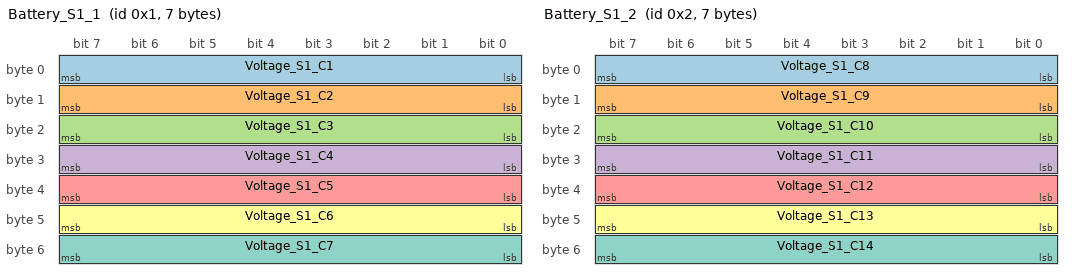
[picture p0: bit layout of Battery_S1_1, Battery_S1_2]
BO_ 1 Battery_S1_1: 7 Vector_XXX
        SG_ Voltage_S1_C1 : 0|8@1+ (0.01,2.2) [0|4.75] "V"
        SG_ Voltage_S1_C2 : 8|8@1+ (0.01,2.2) [0|4.75] "V"
        SG_ Voltage_S1_C3 : 16|8@1+ (0.01,2.2) [0|4.75] "V"
        SG_ Voltage_S1_C4 : 24|8@1+ (0.01,2.2) [0|4.75] "V"
        SG_ Voltage_S1_C5 : 32|8@1+ (0.01,2.2) [0|4.75] "V"
        SG_ Voltage_S1_C6 : 40|8@1+ (0.01,2.2) [0|4.75] "V"
        SG_ Voltage_S1_C7 : 48|8@1+ (0.01,2.2) [0|4.75] "V"

BO_ 2 Battery_S1_2: 7 Vector_XXX
        SG_ Voltage_S1_C8 : 0|8@1+ (0.01,2.2) [0|4.75] "V"
        SG_ Voltage_S1_C9 : 8|8@1+ (0.01,2.2) [0|4.75] "V"
        SG_ Voltage_S1_C10 : 16|8@1+ (0.01,2.2) [0|4.75] "V"
        SG_ Voltage_S1_C11 : 24|8@1+ (0.01,2.2) [0|4.75] "V"
        SG_ Voltage_S1_C12 : 32|8@1+ (0.01,2.2) [0|4.75] "V"
        SG_ Voltage_S1_C13 : 40|8@1+ (0.01,2.2) [0|4.75] "V"
        SG_ Voltage_S1_C14 : 48|8@1+ (0.01,2.2) [0|4.75] "V"

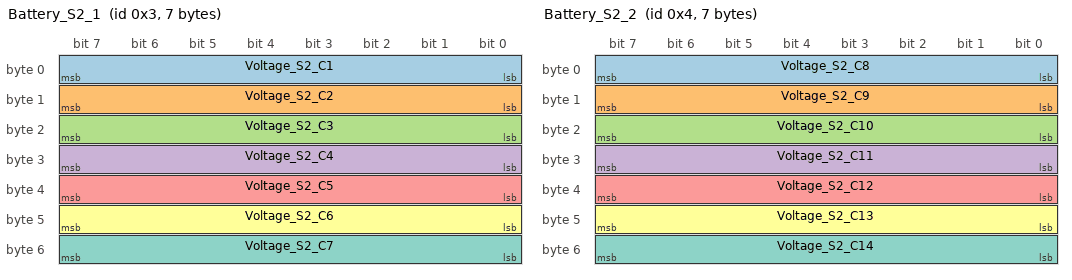
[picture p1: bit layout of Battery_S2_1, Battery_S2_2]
BO_ 3 Battery_S2_1: 7 Vector_XXX
        SG_ Voltage_S2_C1 : 0|8@1+ (0.01,2.2) [0|4.75] "V"
        SG_ Voltage_S2_C2 : 8|8@1+ (0.01,2.2) [0|4.75] "V"
        SG_ Voltage_S2_C3 : 16|8@1+ (0.01,2.2) [0|4.75] "V"
        SG_ Voltage_S2_C4 : 24|8@1+ (0.01,2.2) [0|4.75] "V"
        SG_ Voltage_S2_C5 : 32|8@1+ (0.01,2.2) [0|4.75] "V"
        SG_ Voltage_S2_C6 : 40|8@1+ (0.01,2.2) [0|4.75] "V"
        SG_ Voltage_S2_C7 : 48|8@1+ (0.01,2.2) [0|4.75] "V"

BO_ 4 Battery_S2_2: 7 Vector_XXX
        SG_ Voltage_S2_C8 : 0|8@1+ (0.01,2.2) [0|4.75] "V"
        SG_ Voltage_S2_C9 : 8|8@1+ (0.01,2.2) [0|4.75] "V"
        SG_ Voltage_S2_C10 : 16|8@1+ (0.01,2.2) [0|4.75] "V"
        SG_ Voltage_S2_C11 : 24|8@1+ (0.01,2.2) [0|4.75] "V"
        SG_ Voltage_S2_C12 : 32|8@1+ (0.01,2.2) [0|4.75] "V"
        SG_ Voltage_S2_C13 : 40|8@1+ (0.01,2.2) [0|4.75] "V"
        SG_ Voltage_S2_C14 : 48|8@1+ (0.01,2.2) [0|4.75] "V"

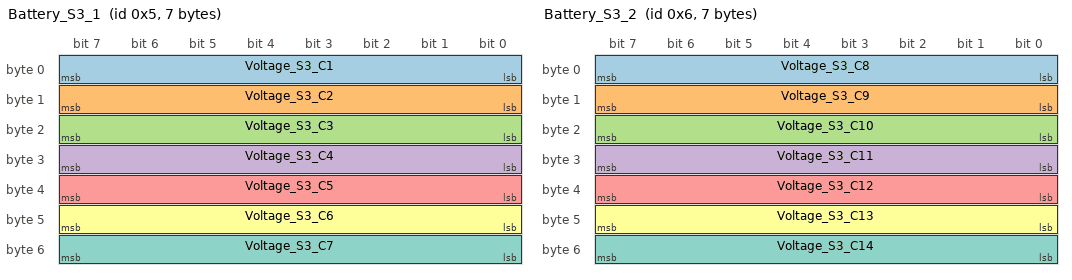
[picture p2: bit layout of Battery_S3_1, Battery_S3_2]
BO_ 5 Battery_S3_1:  7 Vector_XXX
        SG_ Voltage_S3_C1 : 0|8@1+ (0.01,2.2) [0|4.75] "V"
        SG_ Voltage_S3_C2 : 8|8@1+ (0.01,2.2) [0|4.75] "V"
        SG_ Voltage_S3_C3 : 16|8@1+ (0.01,2.2) [0|4.75] "V"
        SG_ Voltage_S3_C4 : 24|8@1+ (0.01,2.2) [0|4.75] "V"
        SG_ Voltage_S3_C5 : 32|8@1+ (0.01,2.2) [0|4.75] "V"
        SG_ Voltage_S3_C6 : 40|8@1+ (0.01,2.2) [0|4.75] "V"
        SG_ Voltage_S3_C7 : 48|8@1+ (0.01,2.2) [0|4.75] "V"

BO_ 6 Battery_S3_2: 7 Vector_XXX
        SG_ Voltage_S3_C8 : 0|8@1+ (0.01,2.2) [0|4.75] "V"
        SG_ Voltage_S3_C9 : 8|8@1+ (0.01,2.2) [0|4.75] "V"
        SG_ Voltage_S3_C10 : 16|8@1+ (0.01,2.2) [0|4.75] "V"
        SG_ Voltage_S3_C11 : 24|8@1+ (0.01,2.2) [0|4.75] "V"
        SG_ Voltage_S3_C12 : 32|8@1+ (0.01,2.2) [0|4.75] "V"
        SG_ Voltage_S3_C13 : 40|8@1+ (0.01,2.2) [0|4.75] "V"
        SG_ Voltage_S3_C14 : 48|8@1+ (0.01,2.2) [0|4.75] "V"

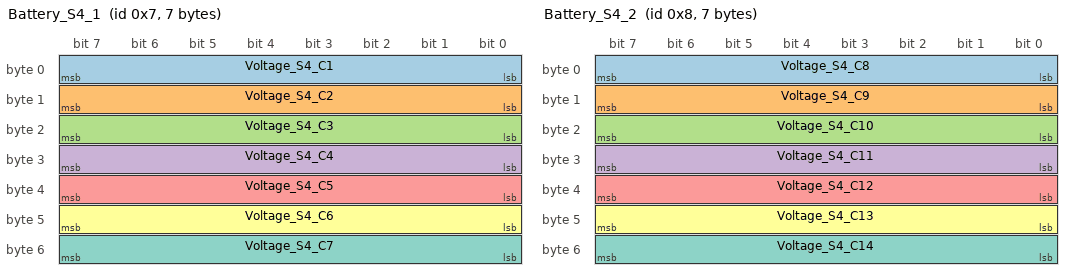
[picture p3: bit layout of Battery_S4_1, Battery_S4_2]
BO_ 7 Battery_S4_1: 7 Vector_XXX
        SG_ Voltage_S4_C1 : 0|8@1+ (0.01,2.2) [0|4.75] "V"
        SG_ Voltage_S4_C2 : 8|8@1+ (0.01,2.2) [0|4.75] "V"
        SG_ Voltage_S4_C3 : 16|8@1+ (0.01,2.2) [0|4.75] "V"
        SG_ Voltage_S4_C4 : 24|8@1+ (0.01,2.2) [0|4.75] "V"
        SG_ Voltage_S4_C5 : 32|8@1+ (0.01,2.2) [0|4.75] "V"
        SG_ Voltage_S4_C6 : 40|8@1+ (0.01,2.2) [0|4.75] "V"
        SG_ Voltage_S4_C7 : 48|8@1+ (0.01,2.2) [0|4.75] "V"

BO_ 8 Battery_S4_2: 7 Vector_XXX
        SG_ Voltage_S4_C8 : 0|8@1+ (0.01,2.2) [0|4.75] "V"
        SG_ Voltage_S4_C9 : 8|8@1+ (0.01,2.2) [0|4.75] "V"
        SG_ Voltage_S4_C10 : 16|8@1+ (0.01,2.2) [0|4.75] "V"
        SG_ Voltage_S4_C11 : 24|8@1+ (0.01,2.2) [0|4.75] "V"
        SG_ Voltage_S4_C12 : 32|8@1+ (0.01,2.2) [0|4.75] "V"
        SG_ Voltage_S4_C13 : 40|8@1+ (0.01,2.2) [0|4.75] "V"
        SG_ Voltage_S4_C14 : 48|8@1+ (0.01,2.2) [0|4.75] "V"

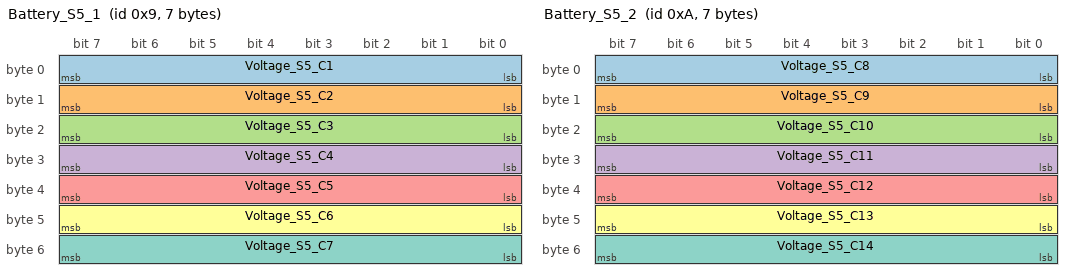
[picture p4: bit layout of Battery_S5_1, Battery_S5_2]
BO_ 9 Battery_S5_1: 7 Vector_XXX
        SG_ Voltage_S5_C1 : 0|8@1+ (0.01,2.2) [0|4.75] "V"
        SG_ Voltage_S5_C2 : 8|8@1+ (0.01,2.2) [0|4.75] "V"
        SG_ Voltage_S5_C3 : 16|8@1+ (0.01,2.2) [0|4.75] "V"
        SG_ Voltage_S5_C4 : 24|8@1+ (0.01,2.2) [0|4.75] "V"
        SG_ Voltage_S5_C5 : 32|8@1+ (0.01,2.2) [0|4.75] "V"
        SG_ Voltage_S5_C6 : 40|8@1+ (0.01,2.2) [0|4.75] "V"
        SG_ Voltage_S5_C7 : 48|8@1+ (0.01,2.2) [0|4.75] "V"

BO_ 10 Battery_S5_2: 7 Vector_XXX
        SG_ Voltage_S5_C8 : 0|8@1+ (0.01,2.2) [0|4.75] "V"
        SG_ Voltage_S5_C9 : 8|8@1+ (0.01,2.2) [0|4.75] "V"
        SG_ Voltage_S5_C10 : 16|8@1+ (0.01,2.2) [0|4.75] "V"
        SG_ Voltage_S5_C11 : 24|8@1+ (0.01,2.2) [0|4.75] "V"
        SG_ Voltage_S5_C12 : 32|8@1+ (0.01,2.2) [0|4.75] "V"
        SG_ Voltage_S5_C13 : 40|8@1+ (0.01,2.2) [0|4.75] "V"
        SG_ Voltage_S5_C14 : 48|8@1+ (0.01,2.2) [0|4.75] "V"

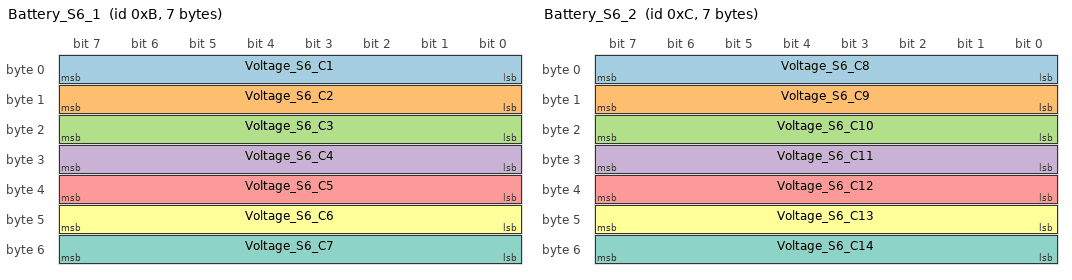
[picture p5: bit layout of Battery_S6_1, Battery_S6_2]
BO_ 11 Battery_S6_1: 7 Vector_XXX
        SG_ Voltage_S6_C1 : 0|8@1+ (0.01,2.2) [0|4.75] "V"
        SG_ Voltage_S6_C2 : 8|8@1+ (0.01,2.2) [0|4.75] "V"
        SG_ Voltage_S6_C3 : 16|8@1+ (0.01,2.2) [0|4.75] "V"
        SG_ Voltage_S6_C4 : 24|8@1+ (0.01,2.2) [0|4.75] "V"
        SG_ Voltage_S6_C5 : 32|8@1+ (0.01,2.2) [0|4.75] "V"
        SG_ Voltage_S6_C6 : 40|8@1+ (0.01,2.2) [0|4.75] "V"
        SG_ Voltage_S6_C7 : 48|8@1+ (0.01,2.2) [0|4.75] "V"

BO_ 12 Battery_S6_2: 7 Vector_XXX
        SG_ Voltage_S6_C8 : 0|8@1+ (0.01,2.2) [0|4.75] "V"
        SG_ Voltage_S6_C9 : 8|8@1+ (0.01,2.2) [0|4.75] "V"
        SG_ Voltage_S6_C10 : 16|8@1+ (0.01,2.2) [0|4.75] "V"
        SG_ Voltage_S6_C11 : 24|8@1+ (0.01,2.2) [0|4.75] "V"
        SG_ Voltage_S6_C12 : 32|8@1+ (0.01,2.2) [0|4.75] "V"
        SG_ Voltage_S6_C13 : 40|8@1+ (0.01,2.2) [0|4.75] "V"
        SG_ Voltage_S6_C14 : 48|8@1+ (0.01,2.2) [0|4.75] "V"

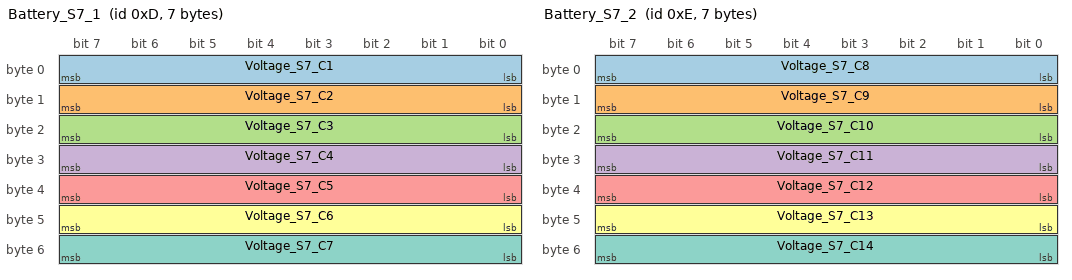
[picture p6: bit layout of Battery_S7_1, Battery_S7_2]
BO_ 13 Battery_S7_1: 7 Vector_XXX
        SG_ Voltage_S7_C1 : 0|8@1+ (0.01,2.2) [0|4.75] "V"
        SG_ Voltage_S7_C2 : 8|8@1+ (0.01,2.2) [0|4.75] "V"
        SG_ Voltage_S7_C3 : 16|8@1+ (0.01,2.2) [0|4.75] "V"
        SG_ Voltage_S7_C4 : 24|8@1+ (0.01,2.2) [0|4.75] "V"
        SG_ Voltage_S7_C5 : 32|8@1+ (0.01,2.2) [0|4.75] "V"
        SG_ Voltage_S7_C6 : 40|8@1+ (0.01,2.2) [0|4.75] "V"
        SG_ Voltage_S7_C7 : 48|8@1+ (0.01,2.2) [0|4.75] "V"

BO_ 14 Battery_S7_2: 7 Vector_XXX
        SG_ Voltage_S7_C8 : 0|8@1+ (0.01,2.2) [0|4.75] "V"
        SG_ Voltage_S7_C9 : 8|8@1+ (0.01,2.2) [0|4.75] "V"
        SG_ Voltage_S7_C10 : 16|8@1+ (0.01,2.2) [0|4.75] "V"
        SG_ Voltage_S7_C11 : 24|8@1+ (0.01,2.2) [0|4.75] "V"
        SG_ Voltage_S7_C12 : 32|8@1+ (0.01,2.2) [0|4.75] "V"
        SG_ Voltage_S7_C13 : 40|8@1+ (0.01,2.2) [0|4.75] "V"
        SG_ Voltage_S7_C14 : 48|8@1+ (0.01,2.2) [0|4.75] "V"

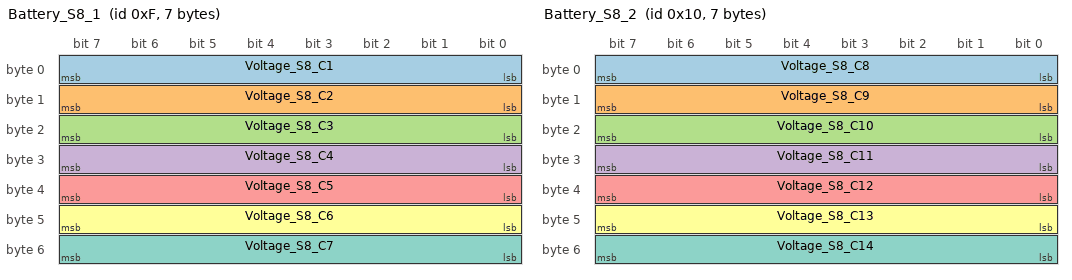
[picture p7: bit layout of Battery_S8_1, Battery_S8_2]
BO_ 15 Battery_S8_1: 7 Vector_XXX
        SG_ Voltage_S8_C1 : 0|8@1+ (0.01,2.2) [0|4.75] "V"
        SG_ Voltage_S8_C2 : 8|8@1+ (0.01,2.2) [0|4.75] "V"
        SG_ Voltage_S8_C3 : 16|8@1+ (0.01,2.2) [0|4.75] "V"
        SG_ Voltage_S8_C4 : 24|8@1+ (0.01,2.2) [0|4.75] "V"
        SG_ Voltage_S8_C5 : 32|8@1+ (0.01,2.2) [0|4.75] "V"
        SG_ Voltage_S8_C6 : 40|8@1+ (0.01,2.2) [0|4.75] "V"
        SG_ Voltage_S8_C7 : 48|8@1+ (0.01,2.2) [0|4.75] "V"

BO_ 16 Battery_S8_2: 7 Vector_XXX
        SG_ Voltage_S8_C8 : 0|8@1+ (0.01,2.2) [0|4.75] "V"
        SG_ Voltage_S8_C9 : 8|8@1+ (0.01,2.2) [0|4.75] "V"
        SG_ Voltage_S8_C10 : 16|8@1+ (0.01,2.2) [0|4.75] "V"
        SG_ Voltage_S8_C11 : 24|8@1+ (0.01,2.2) [0|4.75] "V"
        SG_ Voltage_S8_C12 : 32|8@1+ (0.01,2.2) [0|4.75] "V"
        SG_ Voltage_S8_C13 : 40|8@1+ (0.01,2.2) [0|4.75] "V"
        SG_ Voltage_S8_C14 : 48|8@1+ (0.01,2.2) [0|4.75] "V"

TP_ Voltage_S1_C1 "Battery/S1/Voltage_C1"
TP_ Voltage_S1_C2 "Battery/S1/Voltage_C2"
TP_ Voltage_S1_C3 "Battery/S1/Voltage_C3"
TP_ Voltage_S1_C4 "Battery/S1/Voltage_C4"
TP_ Voltage_S1_C5 "Battery/S1/Voltage_C5"
TP_ Voltage_S1_C6 "Battery/S1/Voltage_C6"
TP_ Voltage_S1_C7 "Battery/S1/Voltage_C7"
TP_ Voltage_S1_C8 "Battery/S1/Voltage_C8"
TP_ Voltage_S1_C9 "Battery/S1/Voltage_C9"
TP_ Voltage_S1_C10 "Battery/S1/Voltage_C10"
TP_ Voltage_S1_C11 "Battery/S1/Voltage_C11"
TP_ Voltage_S1_C12 "Battery/S1/Voltage_C12"
TP_ Voltage_S1_C13 "Battery/S1/Voltage_C13"
TP_ Voltage_S1_C14 "Battery/S1/Voltage_C14"
TP_ Voltage_S2_C1 "Battery/S2/Voltage_C1"
TP_ Voltage_S2_C2 "Battery/S2/Voltage_C2"
TP_ Voltage_S2_C3 "Battery/S2/Voltage_C3"
TP_ Voltage_S2_C4 "Battery/S2/Voltage_C4"
TP_ Voltage_S2_C5 "Battery/S2/Voltage_C5"
TP_ Voltage_S2_C6 "Battery/S2/Voltage_C6"
TP_ Voltage_S2_C7 "Battery/S2/Voltage_C7"
TP_ Voltage_S2_C8 "Battery/S2/Voltage_C8"
TP_ Voltage_S2_C9 "Battery/S2/Voltage_C9"
TP_ Voltage_S2_C10 "Battery/S2/Voltage_C10"
TP_ Voltage_S2_C11 "Battery/S2/Voltage_C11"
TP_ Voltage_S2_C12 "Battery/S2/Voltage_C12"
TP_ Voltage_S2_C13 "Battery/S2/Voltage_C13"
TP_ Voltage_S2_C14 "Battery/S2/Voltage_C14"
TP_ Voltage_S3_C1 "Battery/S3/Voltage_C1"
TP_ Voltage_S3_C2 "Battery/S3/Voltage_C2"
TP_ Voltage_S3_C3 "Battery/S3/Voltage_C3"
TP_ Voltage_S3_C4 "Battery/S3/Voltage_C4"
TP_ Voltage_S3_C5 "Battery/S3/Voltage_C5"
TP_ Voltage_S3_C6 "Battery/S3/Voltage_C6"
TP_ Voltage_S3_C7 "Battery/S3/Voltage_C7"
TP_ Voltage_S3_C8 "Battery/S3/Voltage_C8"
TP_ Voltage_S3_C9 "Battery/S3/Voltage_C9"
TP_ Voltage_S3_C10 "Battery/S3/Voltage_C10"
TP_ Voltage_S3_C11 "Battery/S3/Voltage_C11"
TP_ Voltage_S3_C12 "Battery/S3/Voltage_C12"
TP_ Voltage_S3_C13 "Battery/S3/Voltage_C13"
TP_ Voltage_S3_C14 "Battery/S3/Voltage_C14"
TP_ Voltage_S4_C1 "Battery/S4/Voltage_C1"
TP_ Voltage_S4_C2 "Battery/S4/Voltage_C2"
TP_ Voltage_S4_C3 "Battery/S4/Voltage_C3"
TP_ Voltage_S4_C4 "Battery/S4/Voltage_C4"
TP_ Voltage_S4_C5 "Battery/S4/Voltage_C5"
TP_ Voltage_S4_C6 "Battery/S4/Voltage_C6"
TP_ Voltage_S4_C7 "Battery/S4/Voltage_C7"
TP_ Voltage_S4_C8 "Battery/S4/Voltage_C8"
TP_ Voltage_S4_C9 "Battery/S4/Voltage_C9"
TP_ Voltage_S4_C10 "Battery/S4/Voltage_C10"
TP_ Voltage_S4_C11 "Battery/S4/Voltage_C11"
TP_ Voltage_S4_C12 "Battery/S4/Voltage_C12"
TP_ Voltage_S4_C13 "Battery/S4/Voltage_C13"
TP_ Voltage_S4_C14 "Battery/S4/Voltage_C14"
TP_ Voltage_S5_C1 "Battery/S5/Voltage_C1"
TP_ Voltage_S5_C2 "Battery/S5/Voltage_C2"
TP_ Voltage_S5_C3 "Battery/S5/Voltage_C3"
TP_ Voltage_S5_C4 "Battery/S5/Voltage_C4"
TP_ Voltage_S5_C5 "Battery/S5/Voltage_C5"
TP_ Voltage_S5_C6 "Battery/S5/Voltage_C6"
TP_ Voltage_S5_C7 "Battery/S5/Voltage_C7"
TP_ Voltage_S5_C8 "Battery/S5/Voltage_C8"
TP_ Voltage_S5_C9 "Battery/S5/Voltage_C9"
TP_ Voltage_S5_C10 "Battery/S5/Voltage_C10"
TP_ Voltage_S5_C11 "Battery/S5/Voltage_C11"
TP_ Voltage_S5_C12 "Battery/S5/Voltage_C12"
TP_ Voltage_S5_C13 "Battery/S5/Voltage_C13"
TP_ Voltage_S5_C14 "Battery/S5/Voltage_C14"
TP_ Voltage_S6_C1 "Battery/S6/Voltage_C1"
TP_ Voltage_S6_C2 "Battery/S6/Voltage_C2"
TP_ Voltage_S6_C3 "Battery/S6/Voltage_C3"
TP_ Voltage_S6_C4 "Battery/S6/Voltage_C4"
TP_ Voltage_S6_C5 "Battery/S6/Voltage_C5"
TP_ Voltage_S6_C6 "Battery/S6/Voltage_C6"
TP_ Voltage_S6_C7 "Battery/S6/Voltage_C7"
TP_ Voltage_S6_C8 "Battery/S6/Voltage_C8"
TP_ Voltage_S6_C9 "Battery/S6/Voltage_C9"
TP_ Voltage_S6_C10 "Battery/S6/Voltage_C10"
TP_ Voltage_S6_C11 "Battery/S6/Voltage_C11"
TP_ Voltage_S6_C12 "Battery/S6/Voltage_C12"
TP_ Voltage_S6_C13 "Battery/S6/Voltage_C13"
TP_ Voltage_S6_C14 "Battery/S6/Voltage_C14"
TP_ Voltage_S7_C1 "Battery/S7/Voltage_C1"
TP_ Voltage_S7_C2 "Battery/S7/Voltage_C2"
TP_ Voltage_S7_C3 "Battery/S7/Voltage_C3"
TP_ Voltage_S7_C4 "Battery/S7/Voltage_C4"
TP_ Voltage_S7_C5 "Battery/S7/Voltage_C5"
TP_ Voltage_S7_C6 "Battery/S7/Voltage_C6"
TP_ Voltage_S7_C7 "Battery/S7/Voltage_C7"
TP_ Voltage_S7_C8 "Battery/S7/Voltage_C8"
TP_ Voltage_S7_C9 "Battery/S7/Voltage_C9"
TP_ Voltage_S7_C10 "Battery/S7/Voltage_C10"
TP_ Voltage_S7_C11 "Battery/S7/Voltage_C11"
TP_ Voltage_S7_C12 "Battery/S7/Voltage_C12"
TP_ Voltage_S7_C13 "Battery/S7/Voltage_C13"
TP_ Voltage_S7_C14 "Battery/S7/Voltage_C14"
TP_ Voltage_S8_C1 "Battery/S8/Voltage_C1"
TP_ Voltage_S8_C2 "Battery/S8/Voltage_C2"
TP_ Voltage_S8_C3 "Battery/S8/Voltage_C3"
TP_ Voltage_S8_C4 "Battery/S8/Voltage_C4"
TP_ Voltage_S8_C5 "Battery/S8/Voltage_C5"
TP_ Voltage_S8_C6 "Battery/S8/Voltage_C6"
TP_ Voltage_S8_C7 "Battery/S8/Voltage_C7"
TP_ Voltage_S8_C8 "Battery/S8/Voltage_C8"
TP_ Voltage_S8_C9 "Battery/S8/Voltage_C9"
TP_ Voltage_S8_C10 "Battery/S8/Voltage_C10"
TP_ Voltage_S8_C11 "Battery/S8/Voltage_C11"
TP_ Voltage_S8_C12 "Battery/S8/Voltage_C12"
TP_ Voltage_S8_C13 "Battery/S8/Voltage_C13"
TP_ Voltage_S8_C14 "Battery/S8/Voltage_C14"
